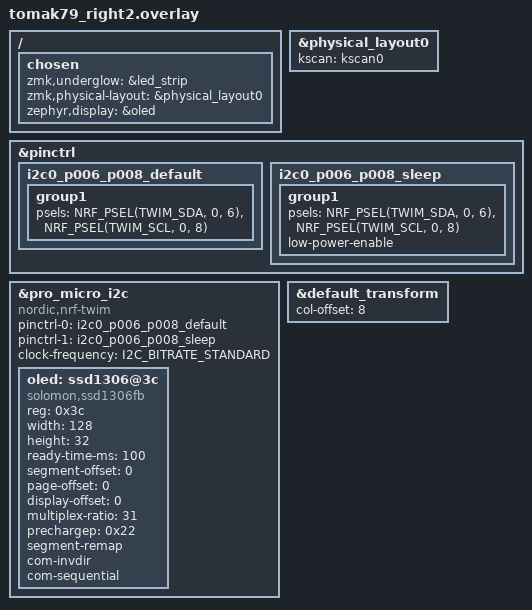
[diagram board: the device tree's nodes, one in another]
#include <dt-bindings/i2c/i2c.h>
#include "tomak79.dtsi"
#include "tomak79_right.dtsi"

/ {
    chosen {
        zmk,underglow = &led_strip;
        zmk,physical-layout = &physical_layout0;
        zephyr,display = &oled;
    };
};

&physical_layout0 {
    kscan = <&kscan0>;
};

&pinctrl {
    i2c0_p006_p008_default: i2c0_p006_p008_default {
        group1 {
            psels = <NRF_PSEL(TWIM_SDA, 0, 6)>,
                <NRF_PSEL(TWIM_SCL, 0, 8)>;
        };
    };

    i2c0_p006_p008_sleep: i2c0_p006_p008_sleep {
        group1 {
            psels = <NRF_PSEL(TWIM_SDA, 0, 6)>,
                <NRF_PSEL(TWIM_SCL, 0, 8)>;
            low-power-enable;
        };
    };

};

&pro_micro_i2c {
    compatible = "nordic,nrf-twim";
    status = "okay";
    pinctrl-0 = <&i2c0_p006_p008_default>;
    pinctrl-1 = <&i2c0_p006_p008_sleep>;
    pinctrl-names = "default", "sleep";
    clock-frequency = <I2C_BITRATE_STANDARD>;

    oled: ssd1306@3c {
        compatible = "solomon,ssd1306fb";
        reg = <0x3c>;
        width = <128>;
        height = <32>;
        ready-time-ms = <100>;
        segment-offset = <0>;
        page-offset = <0>;
        display-offset = <0>;
        multiplex-ratio = <31>;
        prechargep = <0x22>;
        segment-remap;
        com-invdir;
        com-sequential;
    };
};

&default_transform {
    col-offset = <8>;
};
